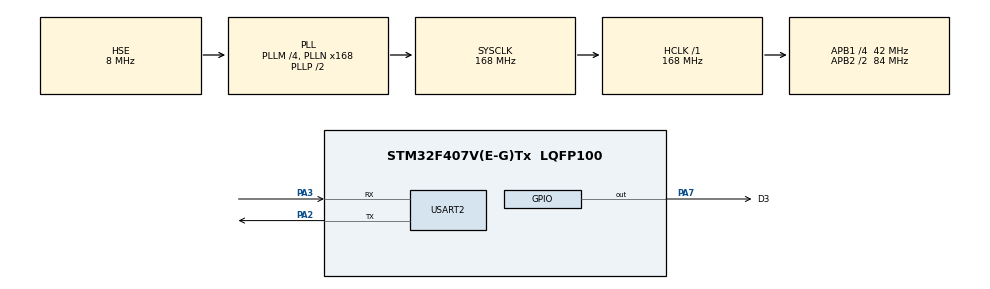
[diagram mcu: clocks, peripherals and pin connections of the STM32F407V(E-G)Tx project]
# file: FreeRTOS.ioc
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FREERTOS.Tasks01=defaultTask,0,64,StartDefaultTask,Default,NULL,Dynamic,NULL,NULL;OSInfo,3,128,StartOSInfo,Default,NULL,Dynamic,NULL,NULL
FREERTOS.configENABLE_BACKWARD_COMPATIBILITY=0
FREERTOS.configGENERATE_RUN_TIME_STATS=1
FREERTOS.configIDLE_SHOULD_YIELD=0
FREERTOS.configMAX_TASK_NAME_LEN=12
FREERTOS.configMINIMAL_STACK_SIZE=64
FREERTOS.configUSE_STATS_FORMATTING_FUNCTIONS=1
FREERTOS.configUSE_TICKLESS_IDLE=1
FREERTOS.configUSE_TRACE_FACILITY=1
Mcu.Family=STM32F4
Mcu.Name=STM32F407V(E-G)Tx
Mcu.Package=LQFP100
NVIC.PriorityGroup=NVIC_PRIORITYGROUP_4
NVIC.TIM6_DAC_IRQn=true\:0\:0\:false\:false\:true\:false\:false
NVIC.TIM7_IRQn=true\:0\:0\:true\:true\:true\:1\:false\:true
NVIC.TimeBase=TIM6_DAC_IRQn
NVIC.TimeBaseIP=TIM6
PA13.Mode=Serial_Wire
PA13.Signal=SYS_JTMS-SWDIO
PA14.Mode=Serial_Wire
PA14.Signal=SYS_JTCK-SWCLK
PA2.Mode=Asynchronous
PA2.Signal=USART2_TX
PA3.Mode=Asynchronous
PA3.Signal=USART2_RX
PA7.GPIO_Label=D3
PA7.GPIO_Speed=GPIO_SPEED_FREQ_VERY_HIGH
PA7.Signal=GPIO_Output
PC14-OSC32_IN.Mode=LSE-External-Oscillator
PC14-OSC32_IN.Signal=RCC_OSC32_IN
PC15-OSC32_OUT.Mode=LSE-External-Oscillator
PC15-OSC32_OUT.Signal=RCC_OSC32_OUT
PH0-OSC_IN.Mode=HSE-External-Oscillator
PH0-OSC_IN.Signal=RCC_OSC_IN
PH1-OSC_OUT.Mode=HSE-External-Oscillator
PH1-OSC_OUT.Signal=RCC_OSC_OUT
ProjectManager.HeapSize=0x800
ProjectManager.StackSize=0x1000
ProjectManager.TargetToolchain=MDK-ARM V5
RCC.48MHZClocksFreq_Value=48000000
RCC.AHBFreq_Value=168000000
RCC.APB1CLKDivider=RCC_HCLK_DIV4
RCC.APB1Freq_Value=42000000
RCC.APB1TimFreq_Value=84000000
RCC.APB2CLKDivider=RCC_HCLK_DIV2
RCC.APB2Freq_Value=84000000
RCC.APB2TimFreq_Value=168000000
RCC.CortexFreq_Value=168000000
RCC.EnbaleCSS=true
RCC.HCLKFreq_Value=168000000
RCC.HSE_VALUE=8000000
RCC.HSI_VALUE=16000000
RCC.PLLM=4
RCC.PLLN=168
RCC.PLLQ=7
RCC.PLLSourceVirtual=RCC_PLLSOURCE_HSE
RCC.SYSCLKFreq_VALUE=168000000
RCC.SYSCLKSource=RCC_SYSCLKSOURCE_PLLCLK
RCC.VCOOutputFreq_Value=336000000
TIM7.Period=100-1
TIM7.Prescaler=168-1
USART2.VirtualMode=VM_ASYNC
VP_FREERTOS_VS_ENABLE.Mode=Enabled
VP_SYS_VS_tim6.Mode=TIM6
VP_TIM7_VS_ClockSourceINT.Mode=Enable_Timer
board=custom

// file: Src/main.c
/**
  ******************************************************************************
  * @file           : main.c
  * @brief          : Main program body
  ******************************************************************************
  * This notice applies to any and all portions of this file
  * that are not between comment pairs USER CODE BEGIN and
  * USER CODE END. Other portions of this file, whether
  * inserted by the user or by software development tools
  * are owned by their respective copyright owners.
  *
  * Copyright (c) 2018 STMicroelectronics International N.V.
  * All rights reserved.
  *
  * Redistribution and use in source and binary forms, with or without
  * modification, are permitted, provided that the following conditions are met:
  *
  * 1. Redistribution of source code must retain the above copyright notice,
  *    this list of conditions and the following disclaimer.
  * 2. Redistributions in binary form must reproduce the above copyright notice,
  *    this list of conditions and the following disclaimer in the documentation
  *    and/or other materials provided with the distribution.
  * 3. Neither the name of STMicroelectronics nor the names of other
  *    contributors to this software may be used to endorse or promote products
  *    derived from this software without specific written permission.
  * 4. This software, including modifications and/or derivative works of this
  *    software, must execute solely and exclusively on microcontroller or
  *    microprocessor devices manufactured by or for STMicroelectronics.
  * 5. Redistribution and use of this software other than as permitted under
  *    this license is void and will automatically terminate your rights under
  *    this license.
  *
  * THIS SOFTWARE IS PROVIDED BY STMICROELECTRONICS AND CONTRIBUTORS "AS IS"
  * AND ANY EXPRESS, IMPLIED OR STATUTORY WARRANTIES, INCLUDING, BUT NOT
  * LIMITED TO, THE IMPLIED WARRANTIES OF MERCHANTABILITY, FITNESS FOR A
  * PARTICULAR PURPOSE AND NON-INFRINGEMENT OF THIRD PARTY INTELLECTUAL PROPERTY
  * RIGHTS ARE DISCLAIMED TO THE FULLEST EXTENT PERMITTED BY LAW. IN NO EVENT
  * SHALL STMICROELECTRONICS OR CONTRIBUTORS BE LIABLE FOR ANY DIRECT, INDIRECT,
  * INCIDENTAL, SPECIAL, EXEMPLARY, OR CONSEQUENTIAL DAMAGES (INCLUDING, BUT NOT
  * LIMITED TO, PROCUREMENT OF SUBSTITUTE GOODS OR SERVICES; LOSS OF USE, DATA,
  * OR PROFITS; OR BUSINESS INTERRUPTION) HOWEVER CAUSED AND ON ANY THEORY OF
  * LIABILITY, WHETHER IN CONTRACT, STRICT LIABILITY, OR TORT (INCLUDING
  * NEGLIGENCE OR OTHERWISE) ARISING IN ANY WAY OUT OF THE USE OF THIS SOFTWARE,
  * EVEN IF ADVISED OF THE POSSIBILITY OF SUCH DAMAGE.
  *
  ******************************************************************************
  */
#include "main.h"
#include "stm32f4xx_hal.h"
#include "cmsis_os.h"
#include "tim.h"
#include "usart.h"
#include "gpio.h"

/* USER CODE BEGIN Includes */
#include "FreeRTOS.h"
/* USER CODE END Includes */

/* USER CODE BEGIN PV */
/* Private variables ---------------------------------------------------------*/
unsigned long RunTimeCounter;
/* USER CODE END PV */

void SystemClock_Config(void);
void MX_FREERTOS_Init(void);
static void MX_NVIC_Init(void);

/* USER CODE BEGIN PFP */
/* Private function prototypes -----------------------------------------------*/

/* USER CODE END PFP */

int main(void)
{

  /* MCU Configuration----------------------------------------------------------*/

  /* Reset of all peripherals, Initializes the Flash interface and the Systick. */
  HAL_Init();

  /* Configure the system clock */
  SystemClock_Config();

  /* Initialize all configured peripherals */
  MX_GPIO_Init();
  MX_USART2_UART_Init();
  MX_TIM7_Init();

  /* Initialize interrupts */
  MX_NVIC_Init();
  /* USER CODE BEGIN 2 */
  HAL_TIM_Base_Start_IT(&htim7);
  /* USER CODE END 2 */

  /* Call init function for freertos objects (in freertos.c) */
  MX_FREERTOS_Init();

  /* Start scheduler */
  osKernelStart();

  /* We should never get here as control is now taken by the scheduler */

  /* Infinite loop */
  while (1)
  {

  }

}

void SystemClock_Config(void)
{

  RCC_OscInitTypeDef RCC_OscInitStruct;
  RCC_ClkInitTypeDef RCC_ClkInitStruct;

    /**Configure the main internal regulator output voltage
    */
  __HAL_RCC_PWR_CLK_ENABLE();

  __HAL_PWR_VOLTAGESCALING_CONFIG(PWR_REGULATOR_VOLTAGE_SCALE1);

    /**Initializes the CPU, AHB and APB busses clocks
    */
  RCC_OscInitStruct.OscillatorType = RCC_OSCILLATORTYPE_HSE;
  RCC_OscInitStruct.HSEState = RCC_HSE_ON;
  RCC_OscInitStruct.PLL.PLLState = RCC_PLL_ON;
  RCC_OscInitStruct.PLL.PLLSource = RCC_PLLSOURCE_HSE;
  RCC_OscInitStruct.PLL.PLLM = 4;
  RCC_OscInitStruct.PLL.PLLN = 168;
  RCC_OscInitStruct.PLL.PLLP = RCC_PLLP_DIV2;
  RCC_OscInitStruct.PLL.PLLQ = 7;
  if (HAL_RCC_OscConfig(&RCC_OscInitStruct) != HAL_OK)
  {
    _Error_Handler(__FILE__, __LINE__);
  }

    /**Initializes the CPU, AHB and APB busses clocks
    */
  RCC_ClkInitStruct.ClockType = RCC_CLOCKTYPE_HCLK|RCC_CLOCKTYPE_SYSCLK
                              |RCC_CLOCKTYPE_PCLK1|RCC_CLOCKTYPE_PCLK2;
  RCC_ClkInitStruct.SYSCLKSource = RCC_SYSCLKSOURCE_PLLCLK;
  RCC_ClkInitStruct.AHBCLKDivider = RCC_SYSCLK_DIV1;
  RCC_ClkInitStruct.APB1CLKDivider = RCC_HCLK_DIV4;
  RCC_ClkInitStruct.APB2CLKDivider = RCC_HCLK_DIV2;

  if (HAL_RCC_ClockConfig(&RCC_ClkInitStruct, FLASH_LATENCY_5) != HAL_OK)
  {
    _Error_Handler(__FILE__, __LINE__);
  }

    /**Enables the Clock Security System
    */
  HAL_RCC_EnableCSS();

    /**Configure the Systick interrupt time
    */
  HAL_SYSTICK_Config(HAL_RCC_GetHCLKFreq()/1000);

    /**Configure the Systick
    */
  HAL_SYSTICK_CLKSourceConfig(SYSTICK_CLKSOURCE_HCLK);

  /* SysTick_IRQn interrupt configuration */
  HAL_NVIC_SetPriority(SysTick_IRQn, 15, 0);
}

/**
  * @brief NVIC Configuration.
  * @retval None
  */
static void MX_NVIC_Init(void)
{
  /* TIM7_IRQn interrupt configuration */
  HAL_NVIC_SetPriority(TIM7_IRQn, 0, 0);
  HAL_NVIC_EnableIRQ(TIM7_IRQn);
}

void HAL_TIM_PeriodElapsedCallback(TIM_HandleTypeDef *htim)
{
  if (htim->Instance == TIM6) {
    HAL_IncTick();
  }
  /* USER CODE BEGIN Callback 1 */
  if (htim->Instance == TIM7) {
    RunTimeCounter++;
  }
  /* USER CODE END Callback 1 */
}

void _Error_Handler(char *file, int line)
{
  while(1)
  {
  }
}

/************************ (C) COPYRIGHT STMicroelectronics *****END OF FILE****/

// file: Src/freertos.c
/* USER CODE BEGIN Header */
/**
  ******************************************************************************
  * File Name          : freertos.c
  * Description        : Code for freertos applications
  ******************************************************************************
  * This notice applies to any and all portions of this file
  * that are not between comment pairs USER CODE BEGIN and
  * USER CODE END. Other portions of this file, whether
  * inserted by the user or by software development tools
  * are owned by their respective copyright owners.
  *
  * Copyright (c) 2018 STMicroelectronics International N.V.
  * All rights reserved.
  *
  * Redistribution and use in source and binary forms, with or without
  * modification, are permitted, provided that the following conditions are met:
  *
  * 1. Redistribution of source code must retain the above copyright notice,
  *    this list of conditions and the following disclaimer.
  * 2. Redistributions in binary form must reproduce the above copyright notice,
  *    this list of conditions and the following disclaimer in the documentation
  *    and/or other materials provided with the distribution.
  * 3. Neither the name of STMicroelectronics nor the names of other
  *    contributors to this software may be used to endorse or promote products
  *    derived from this software without specific written permission.
  * 4. This software, including modifications and/or derivative works of this
  *    software, must execute solely and exclusively on microcontroller or
  *    microprocessor devices manufactured by or for STMicroelectronics.
  * 5. Redistribution and use of this software other than as permitted under
  *    this license is void and will automatically terminate your rights under
  *    this license.
  *
  * THIS SOFTWARE IS PROVIDED BY STMICROELECTRONICS AND CONTRIBUTORS "AS IS"
  * AND ANY EXPRESS, IMPLIED OR STATUTORY WARRANTIES, INCLUDING, BUT NOT
  * LIMITED TO, THE IMPLIED WARRANTIES OF MERCHANTABILITY, FITNESS FOR A
  * PARTICULAR PURPOSE AND NON-INFRINGEMENT OF THIRD PARTY INTELLECTUAL PROPERTY
  * RIGHTS ARE DISCLAIMED TO THE FULLEST EXTENT PERMITTED BY LAW. IN NO EVENT
  * SHALL STMICROELECTRONICS OR CONTRIBUTORS BE LIABLE FOR ANY DIRECT, INDIRECT,
  * INCIDENTAL, SPECIAL, EXEMPLARY, OR CONSEQUENTIAL DAMAGES (INCLUDING, BUT NOT
  * LIMITED TO, PROCUREMENT OF SUBSTITUTE GOODS OR SERVICES; LOSS OF USE, DATA,
  * OR PROFITS; OR BUSINESS INTERRUPTION) HOWEVER CAUSED AND ON ANY THEORY OF
  * LIABILITY, WHETHER IN CONTRACT, STRICT LIABILITY, OR TORT (INCLUDING
  * NEGLIGENCE OR OTHERWISE) ARISING IN ANY WAY OUT OF THE USE OF THIS SOFTWARE,
  * EVEN IF ADVISED OF THE POSSIBILITY OF SUCH DAMAGE.
  *
  ******************************************************************************
  */
/* USER CODE END Header */

#include "FreeRTOS.h"
#include "task.h"
#include "main.h"
#include "cmsis_os.h"

/* USER CODE BEGIN Includes */
#include "gpio.h"

#include "printf_scanf.h"
/* USER CODE END Includes */

/* USER CODE BEGIN Variables */
extern unsigned long RunTimeCounter;
/* USER CODE END Variables */
osThreadId defaultTaskHandle;
osThreadId OSInfoHandle;

void StartDefaultTask(void const * argument);
void StartOSInfo(void const * argument);

void MX_FREERTOS_Init(void); /* (MISRA C 2004 rule 8.1) */

/* Pre/Post sleep processing prototypes */
void PreSleepProcessing(uint32_t *ulExpectedIdleTime);
void PostSleepProcessing(uint32_t *ulExpectedIdleTime);

/* Hook prototypes */
void configureTimerForRunTimeStats(void);
unsigned long getRunTimeCounterValue(void);

/* USER CODE BEGIN 1 */
/* Functions needed when configGENERATE_RUN_TIME_STATS is on */
__weak void configureTimerForRunTimeStats(void)
{
 RunTimeCounter=0UL;
}

__weak unsigned long getRunTimeCounterValue(void)
{
return RunTimeCounter;
}
/* USER CODE END 1 */

/* USER CODE BEGIN PREPOSTSLEEP */
__weak void PreSleepProcessing(uint32_t *ulExpectedIdleTime)
{
/* place for user code */
}

__weak void PostSleepProcessing(uint32_t *ulExpectedIdleTime)
{
/* place for user code */
}
/* USER CODE END PREPOSTSLEEP */

void MX_FREERTOS_Init(void) {

  /* Create the thread(s) */
  /* definition and creation of defaultTask */
  osThreadDef(defaultTask, StartDefaultTask, osPriorityNormal, 0, 64);
  defaultTaskHandle = osThreadCreate(osThread(defaultTask), NULL);

  /* definition and creation of OSInfo */
  osThreadDef(OSInfo, StartOSInfo, osPriorityRealtime, 0, 128);
  OSInfoHandle = osThreadCreate(osThread(OSInfo), NULL);

}

void StartDefaultTask(void const * argument)
{

  /* USER CODE BEGIN StartDefaultTask */
  /* Infinite loop */
  for(;;)
  {
			 HAL_GPIO_TogglePin(GPIOA,D3_Pin);
    osDelay(500);
  }
  /* USER CODE END StartDefaultTask */
}

void StartOSInfo(void const * argument)
{
  /* USER CODE BEGIN StartOSInfo */
	 uint8_t buf[64];
	 printf("OS information Task\r\n");
  /* Infinite loop */
  for(;;)
  {
			 osThreadList(buf);
			 printf("Name        Status    pri     stack   Number\r\n");
			 printf("%s\r\n",buf);
				vTaskGetRunTimeStats( (char *) buf );
			 printf("Name        Counte       percentage\r\n");
			 printf("%s\r\n",buf);

    osDelay(3000);
  }
  /* USER CODE END StartOSInfo */
}

/************************ (C) COPYRIGHT STMicroelectronics *****END OF FILE****/
